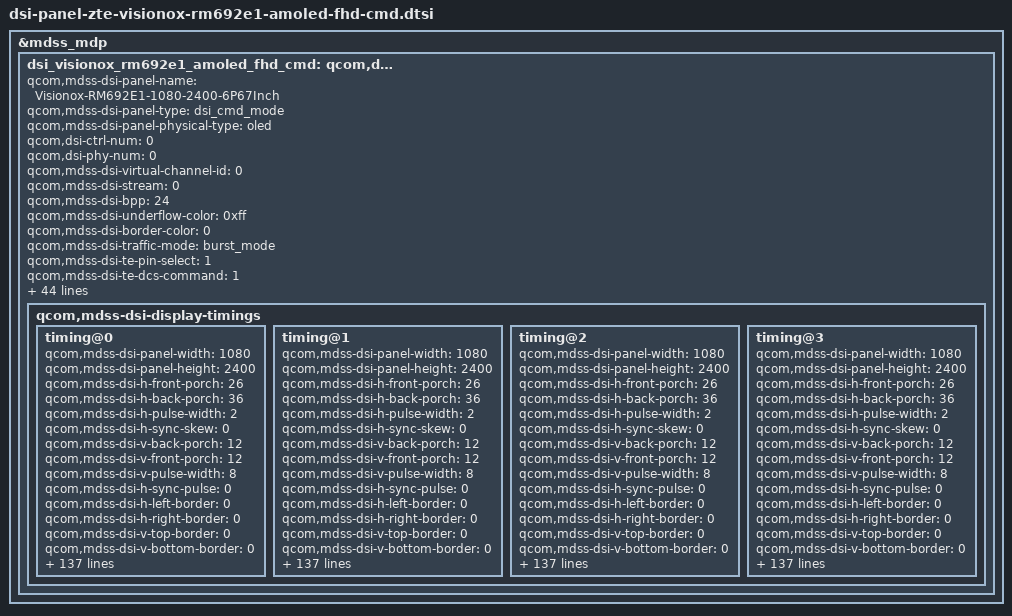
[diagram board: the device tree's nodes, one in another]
&mdss_mdp {
	dsi_visionox_rm692e1_amoled_fhd_cmd: qcom,dsi_visionox_rm692e1_cmd_display {
		qcom,mdss-dsi-panel-name = "Visionox-RM692E1-1080-2400-6P67Inch";
		qcom,mdss-dsi-panel-type = "dsi_cmd_mode";
		qcom,mdss-dsi-panel-physical-type = "oled";
		qcom,dsi-ctrl-num = <0>;
		qcom,dsi-phy-num = <0>;
		qcom,mdss-dsi-virtual-channel-id = <0>;
		qcom,mdss-dsi-stream = <0>;
		qcom,mdss-dsi-bpp = <24>;
		qcom,mdss-dsi-underflow-color = <0xff>;
		qcom,mdss-dsi-border-color = <0>;
		qcom,mdss-dsi-traffic-mode = "burst_mode";
		qcom,mdss-dsi-te-pin-select = <1>;
		qcom,mdss-dsi-te-dcs-command = <1>;
		qcom,mdss-dsi-te-check-enable;
		qcom,mdss-dsi-te-using-te-pin;
		qcom,mdss-dsi-bllp-eof-power-mode;
		qcom,mdss-dsi-bllp-power-mode;
		qcom,mdss-dsi-lane-0-state;
		qcom,mdss-dsi-lane-1-state;
		qcom,mdss-dsi-lane-2-state;
		qcom,mdss-dsi-lane-3-state;
		qcom,mdss-dsi-lp11-init;
		qcom,mdss-dsi-reset-sequence = <1 10 0 20 1 180>;
		qcom,mdss-dsi-tx-eot-append;
		qcom,mdss-dsi-post-init-delay = <1>;
		qcom,mdss-dsi-dma-trigger = "trigger_sw";
		qcom,mdss-dsi-mdp-trigger = "none";
		qcom,mdss-dsi-bl-min-level = <16>;
		qcom,mdss-dsi-bl-max-level = <2047>;
		qcom,bl-dsc-cmd-state = "dsi_lp_mode";
		qcom,mdss-dsi-bl-pmic-control-type = "bl_ctrl_dcs";
		qcom,mdss-dsi-panel-hdr-enabled;
		qcom,mdss-dsi-panel-hdr-color-primaries = <14500 15500 34015 15980 13030 34670 6950 2565>;
		qcom,mdss-dsi-panel-peak-brightness = <6680000>;
		qcom,mdss-dsi-panel-blackness-level = <20>;
		qcom,mdss-pan-physical-width-dimension = <69>;
		qcom,mdss-pan-physical-height-dimension = <155>;
		zte,lcd_dimreg_value = <40>;
		zte,lcd_close_dimreg_value = <32>;
		zte,lcd_aod_bl_reg51_control;
		zte,lcd_hbm_max_bl = <4095>;
		qcom,panel-supply-entries = <&dsi_panel_pwr_supply>;
		qcom,mdss-brightness-max-level = <255>;
		qcom,platform-reset-gpio = <&tlmm 24 0>;
		zte,disp_iovdd_en_gpio = <&pm8350_gpios 9 1>;
		qcom,mdss-dsi-bl-inverted-dbv;
		qcom,dsi-select-clocks = "mux_byte_clk0", "mux_pixel_clk0";
		qcom,dsi-panel-gpio-address = <0xf100000 0x1000>;
		qcom,dsi-panel-gpio-pins = <12 24 82>;
		qcom,dsi-panel-gpio-names = "reg-gpio", "reset-gpio", "platform-te-gpio";
		qcom,fod-dim-lut = <
			/* brightness alpha */
			0   244
			8   241
			16  239
			24  236
			32  235
			41  235
			49  235
			57  235
			65  235
			74  235
			82  226
			90  222
			98  218
			107 212
			115 206
			123 200
			131 190
			140 185
			148 181
			156 177
			164 173
			173 169
			181 165
			189 161
			197 157
			206 148
			214 140
			222 134
			230 130
			239 126
			247 112
			255 104
		>;

		qcom,mdss-dsi-display-timings {
			timing@0 {
				qcom,mdss-dsi-panel-width = <1080>;
				qcom,mdss-dsi-panel-height = <2400>;
				qcom,mdss-dsi-h-front-porch = <26>;
				qcom,mdss-dsi-h-back-porch = <36>;
				qcom,mdss-dsi-h-pulse-width = <2>;
				qcom,mdss-dsi-h-sync-skew = <0>;
				qcom,mdss-dsi-v-back-porch = <12>;
				qcom,mdss-dsi-v-front-porch = <12>;
				qcom,mdss-dsi-v-pulse-width = <8>;
				qcom,mdss-dsi-h-sync-pulse = <0>;
				qcom,mdss-dsi-h-left-border = <0>;
				qcom,mdss-dsi-h-right-border = <0>;
				qcom,mdss-dsi-v-top-border = <0>;
				qcom,mdss-dsi-v-bottom-border = <0>;
				qcom,mdss-dsi-panel-framerate = <60>;
				qcom,mdss-dsi-panel-clockrate = <925100000>;
				zte,mdss-dsi-60fps-to-90fps-commands = [15 01 00 00 00 00 02 fe 40
					15 01 00 00 00 00 02 bd 05
					15 01 00 00 00 00 02 fe 00
				];
				zte,mdss-dsi-60fps-to-90fps-commands-state = "dsi_lp_mode";
				zte,mdss-dsi-60fps-to-120fps-commands = [15 01 00 00 00 00 02 fe 00
					15 01 00 00 14 00 02 53 20
					15 01 00 00 32 00 02 03 06
					15 01 00 00 00 00 02 fe 00
					15 01 00 00 00 00 02 53 28
				];
				zte,mdss-dsi-60fps-to-120fps-commands-state = "dsi_lp_mode";
				zte,mdss-dsi-60fps-to-144fps-commands = [15 01 00 00 00 00 02 fe 00
					15 01 00 00 14 00 02 53 20
					15 01 00 00 32 00 02 03 06
					15 01 00 00 00 00 02 fe 40
					15 01 00 00 00 00 02 bd 07
					15 01 00 00 00 00 02 fe 00
					15 01 00 00 00 00 02 53 28
				];
				zte,mdss-dsi-60fps-to-144fps-commands-state = "dsi_lp_mode";
				zte,mdss-dsi-60fps-to-aod-commands = [15 01 00 00 00 00 02 fe 22
					15 01 00 00 00 00 02 5f 03
					15 01 00 00 00 00 02 fe 40
					15 01 00 00 00 00 02 15 13
					15 01 00 00 00 00 02 fe 00
					05 01 00 00 00 00 02 39 00
					15 01 00 00 00 00 02 fe 00
				];
				zte,mdss-dsi-60fps-to-aod-commands-state = "dsi_lp_mode";
				zte,mdss-dsi-90fps-to-60fps-commands = [15 01 00 00 00 00 02 fe 40
					15 01 00 00 00 00 02 bd 00
					15 01 00 00 00 00 02 fe 00
				];
				zte,mdss-dsi-90fps-to-60fps-commands-state = "dsi_lp_mode";
				zte,mdss-dsi-90fps-to-120fps-commands = [15 01 00 00 00 00 02 fe 00
					15 01 00 00 14 00 02 53 20
					15 01 00 00 00 00 02 fe 40
					15 01 00 00 00 00 02 bd 00
					15 01 00 00 00 00 02 fe 00
					15 01 00 00 32 00 02 03 06
					15 01 00 00 00 00 02 fe 00
					15 01 00 00 00 00 02 53 28
				];
				zte,mdss-dsi-90fps-to-120fps-commands-state = "dsi_lp_mode";
				zte,mdss-dsi-90fps-to-144fps-commands = [15 01 00 00 00 00 02 fe 00
					15 01 00 00 14 00 02 53 20
					15 01 00 00 00 00 02 fe 40
					15 01 00 00 00 00 02 bd 00
					15 01 00 00 00 00 02 fe 00
					15 01 00 00 32 00 02 03 06
					15 01 00 00 00 00 02 fe 40
					15 01 00 00 00 00 02 bd 07
					15 01 00 00 00 00 02 fe 00
					15 01 00 00 00 00 02 53 28
				];
				zte,mdss-dsi-90fps-to-144fps-commands-state = "dsi_lp_mode";
				zte,mdss-dsi-90fps-to-aod-commands = [15 01 00 00 00 00 02 fe 22
					15 01 00 00 00 00 02 5f 02
					15 01 00 00 00 00 02 fe 40
					15 01 00 00 00 00 02 bd 00
					15 01 00 00 00 00 02 fe 00
					05 01 00 00 00 00 02 39 00
					15 01 00 00 00 00 02 fe 00
				];
				zte,mdss-dsi-90fps-to-aod-commands-state = "dsi_lp_mode";
				zte,mdss-dsi-120fps-to-60fps-commands = [15 01 00 00 00 00 02 fe 00
					15 01 00 00 14 00 02 53 20
					15 01 00 00 32 00 02 03 00
					15 01 00 00 00 00 02 fe 00
					15 01 00 00 00 00 02 53 28
				];
				zte,mdss-dsi-120fps-to-60fps-commands-state = "dsi_lp_mode";
				zte,mdss-dsi-120fps-to-90fps-commands = [15 01 00 00 00 00 02 fe 00
					15 01 00 00 14 00 02 53 20
					15 01 00 00 32 00 02 03 00
					15 01 00 00 00 00 02 fe 40
					15 01 00 00 00 00 02 bd 05
					15 01 00 00 00 00 02 fe 00
					15 01 00 00 00 00 02 53 28
				];
				zte,mdss-dsi-120fps-to-90fps-commands-state = "dsi_lp_mode";
				zte,mdss-dsi-120fps-to-144fps-commands = [15 01 00 00 00 00 02 fe 40
					15 01 00 00 00 00 02 bd 07
					15 01 00 00 00 00 02 fe 00
				];
				zte,mdss-dsi-120fps-to-144fps-commands-state = "dsi_lp_mode";
				zte,mdss-dsi-120fps-to-aod-commands = [15 01 00 00 00 00 02 fe 22
					15 01 00 00 00 00 02 5f 02
					15 01 00 00 00 00 02 fe 00
					15 01 00 00 32 00 02 03 00
					15 01 00 00 00 00 02 fe 00
					05 01 00 00 00 00 02 39 00
				];
				zte,mdss-dsi-120fps-to-aod-commands-state = "dsi_lp_mode";
				zte,mdss-dsi-144fps-to-60fps-commands = [15 01 00 00 00 00 02 fe 00
					15 01 00 00 14 00 02 53 20
					15 01 00 00 00 00 02 fe 40
					15 01 00 00 00 00 02 bd 06
					15 01 00 00 00 00 02 fe 00
					15 01 00 00 32 00 02 03 00
					15 01 00 00 00 00 02 53 28
				];
				zte,mdss-dsi-144fps-to-60fps-commands-state = "dsi_lp_mode";
				zte,mdss-dsi-144fps-to-90fps-commands = [15 01 00 00 00 00 02 fe 00
					15 01 00 00 14 00 02 53 20
					15 01 00 00 00 00 02 fe 40
					15 01 00 00 00 00 02 bd 06
					15 01 00 00 00 00 02 fe 00
					15 01 00 00 32 00 02 03 00
					15 01 00 00 00 00 02 fe 40
					15 01 00 00 00 00 02 bd 05
					15 01 00 00 00 00 02 fe 00
					15 01 00 00 00 00 02 53 20
				];
				zte,mdss-dsi-144fps-to-90fps-commands-state = "dsi_lp_mode";
				zte,mdss-dsi-144fps-to-120fps-commands = [15 01 00 00 00 00 02 fe 40
					15 01 00 00 00 00 02 bd 06
					15 01 00 00 00 00 02 fe 00
				];
				zte,mdss-dsi-144fps-to-120fps-commands-state = "dsi_lp_mode";
				zte,mdss-dsi-144fps-to-aod-commands = [15 01 00 00 00 00 02 fe 22
					15 01 00 00 00 00 02 5f 02
					15 01 00 00 00 00 02 fe 40
					15 01 00 00 00 00 02 bd 06 
					15 01 00 00 00 00 02 fe 00
					15 01 00 00 32 00 02 03 00
					15 01 00 00 00 00 02 fe 00
					05 01 00 00 00 00 02 39 00
				];
				zte,mdss-dsi-144fps-to-aod-commands-state = "dsi_lp_mode";
				qcom,mdss-dsi-on-command = [15 01 00 00 00 00 02 fe 34
					15 01 00 00 00 00 02 47 03
					15 01 00 00 00 00 02 48 00
					15 01 00 00 00 00 02 00 00
					15 01 00 00 00 00 02 fe 34
					15 01 00 00 00 00 02 9f 38
					15 01 00 00 00 00 02 a0 04
					15 01 00 00 00 00 02 1e 33
					15 01 00 00 00 00 02 1f fc
					15 01 00 00 00 00 02 20 fc
					15 01 00 00 00 00 02 22 fc
					15 01 00 00 00 00 02 21 73
					15 01 00 00 00 00 02 23 f8
					15 01 00 00 00 00 02 24 77
					15 01 00 00 00 00 02 25 f8
					15 01 00 00 00 00 02 26 f8
					15 01 00 00 00 00 02 2f 00
					15 01 00 00 00 00 02 30 00
					15 01 00 00 00 00 02 31 00
					15 01 00 00 00 00 02 32 00
					15 01 00 00 00 00 02 33 00
					15 01 00 00 00 00 02 34 00
					15 01 00 00 00 00 02 35 01
					15 01 00 00 00 00 02 36 47
					15 01 00 00 00 00 02 37 02
					15 01 00 00 00 00 02 38 3e
					15 01 00 00 00 00 02 39 03
					15 01 00 00 00 00 02 3a 33
					15 01 00 00 00 00 02 3b 00
					15 01 00 00 00 00 02 3d 00
					15 01 00 00 00 00 02 3f 00
					15 01 00 00 00 00 02 40 00
					15 01 00 00 00 00 02 41 00
					15 01 00 00 00 00 02 42 00
					15 01 00 00 00 00 02 fe 34
					15 01 00 00 00 00 02 49 75
					15 01 00 00 00 00 02 fe 76
					15 01 00 00 00 00 02 00 3c
					15 01 00 00 00 00 02 09 03
					15 01 00 00 00 00 02 0a 00
					15 01 00 00 00 00 02 0b 06
					15 01 00 00 00 00 02 0c 70
					15 01 00 00 00 00 02 0d 76
					15 01 00 00 00 00 02 0e 0d
					15 01 00 00 00 00 02 0f 03
					15 01 00 00 00 00 02 10 00
					15 01 00 00 00 00 02 11 00
					15 01 00 00 00 00 02 12 80
					15 01 00 00 00 00 02 13 76
					15 01 00 00 00 00 02 14 0d
					15 01 00 00 00 00 02 fe 76
					15 01 00 00 00 00 02 70 fe
					15 01 00 00 00 00 02 71 40
					15 01 00 00 00 00 02 72 bd
					15 01 00 00 00 00 02 73 06
					15 01 00 00 00 00 02 74 ff
					15 01 00 00 00 00 02 75 01
					15 01 00 00 00 00 02 76 02
					15 01 00 00 00 00 02 77 fe
					15 01 00 00 00 00 02 78 62
					15 01 00 00 00 00 02 79 ee
					15 01 00 00 00 00 02 7a 20
					15 01 00 00 00 00 02 7b fe
					15 01 00 00 00 00 02 7c 00
					15 01 00 00 00 00 02 80 fe
					15 01 00 00 00 00 02 81 40
					15 01 00 00 00 00 02 82 bd
					15 01 00 00 00 00 02 83 00
					15 01 00 00 00 00 02 84 ff
					15 01 00 00 00 00 02 85 01
					15 01 00 00 00 00 02 86 02
					15 01 00 00 00 00 02 87 fe
					15 01 00 00 00 00 02 88 62
					15 01 00 00 00 00 02 89 ee
					15 01 00 00 00 00 02 8a 10
					15 01 00 00 00 00 02 8b fe
					15 01 00 00 00 00 02 8c 00
					15 01 00 00 00 00 02 fe d0
					15 01 00 00 00 00 02 14 c0
					15 01 00 00 00 00 02 15 c0
					15 01 00 00 00 00 02 fe 12
					15 01 00 00 00 00 02 83 20
					15 01 00 00 00 00 02 fe 00
					15 01 00 00 00 00 02 fa 01
					15 01 00 00 00 00 02 c2 08
					15 01 00 00 00 00 02 35 00
					39 01 00 00 00 00 03 51 00 00
					15 01 00 00 00 00 02 fe b0
					15 01 00 00 00 00 02 27 7f
					15 01 00 00 00 00 02 fe 62
					15 01 00 00 00 00 02 0f f0
					15 01 00 00 00 00 02 10 00
					15 01 00 00 00 00 02 fe 60
					15 01 00 00 00 00 02 7e 50
					15 01 00 00 00 00 02 80 98
					15 01 00 00 00 00 02 81 20
					15 01 00 00 00 00 02 0d 50
					15 01 00 00 00 00 02 0f 98
					15 01 00 00 00 00 02 10 20
					15 01 00 00 00 00 02 28 50
					15 01 00 00 00 00 02 2a 90
					15 01 00 00 00 00 02 2b 05
					15 01 00 00 00 00 02 47 50
					15 01 00 00 00 00 02 49 90
					15 01 00 00 00 00 02 4a 05
					15 01 00 00 00 00 02 fe 60
					15 01 00 00 00 00 02 92 e5
					15 01 00 00 00 00 02 94 00
					15 01 00 00 00 00 02 fe d4
					15 01 00 00 00 00 02 14 83
					15 01 00 00 00 00 02 1e 00
					15 01 00 00 00 00 02 1f 08
					15 01 00 00 00 00 02 20 0c
					15 01 00 00 00 00 02 21 03
					15 01 00 00 00 00 02 22 8e
					15 01 00 00 00 00 02 23 03
					15 01 00 00 00 00 02 24 e8
					15 01 00 00 00 00 02 25 00
					15 01 00 00 00 00 02 26 08
					15 01 00 00 00 00 02 27 0c
					15 01 00 00 00 00 02 28 03
					15 01 00 00 00 00 02 29 8e
					15 01 00 00 00 00 02 2a 03
					15 01 00 00 00 00 02 2b e8
					15 01 00 00 00 00 02 2d 00
					15 01 00 00 00 00 02 2f 08
					15 01 00 00 00 00 02 30 0c
					15 01 00 00 00 00 02 31 03
					15 01 00 00 00 00 02 32 8e
					15 01 00 00 00 00 02 33 03
					15 01 00 00 00 00 02 34 e8
					15 01 00 00 00 00 02 35 00
					15 01 00 00 00 00 02 36 08
					15 01 00 00 00 00 02 37 0c
					15 01 00 00 00 00 02 38 03
					15 01 00 00 00 00 02 39 8e
					15 01 00 00 00 00 02 3a 03
					15 01 00 00 00 00 02 3b e8
					15 01 00 00 00 00 02 fe 14
					15 01 00 00 00 00 02 a2 01
					15 01 00 00 00 00 02 51 80
					15 01 00 00 00 00 02 7b 00
					15 01 00 00 00 00 02 fe 40
					15 01 00 00 00 00 02 25 1a
					15 01 00 00 00 00 02 26 1d
					15 01 00 00 00 00 02 ac 84
					15 01 00 00 00 00 02 31 00
					15 01 00 00 00 00 02 35 00
					15 01 00 00 00 00 02 fe 00
					05 01 00 00 50 00 02 11 00
					05 01 00 00 0a 00 02 29 00
				];
				qcom,mdss-dsi-off-command = [39 01 00 00 14 00 03 51 00 00
					05 01 00 00 32 00 02 28 00
					05 01 00 00 50 00 02 10 00
				];
				qcom,mdss-dsi-on-command-state = "dsi_lp_mode";
				qcom,mdss-dsi-off-command-state = "dsi_lp_mode";
				qcom,mdss-dsi-lp1-command = [15 01 00 00 00 00 02 fe 22
					15 01 00 00 00 00 02 5f 03
					15 01 00 00 00 00 02 fe 40
					15 01 00 00 00 00 02 15 13
					15 01 00 00 00 00 02 fe 00
					05 01 00 00 00 00 02 39 00
					15 01 00 00 00 00 02 fe 00
				];
				qcom,mdss-dsi-lp1-command-state = "dsi_lp_mode";
				qcom,mdss-dsi-nolp-command = [15 01 00 00 00 00 02 fe 22
					15 01 00 00 00 00 02 5f 01
					15 01 00 00 00 00 02 fe 40
					15 01 00 00 00 00 02 15 4f
					15 01 00 00 00 00 02 fe 00
					05 01 00 00 00 00 02 38 00
					15 01 00 00 00 00 02 fe 00
				];
				qcom,mdss-dsi-nolp-command-state = "dsi_lp_mode";
				zte,mdss-dsi-aod-low-commands = [15 01 00 00 00 00 02 fe 00
					39 01 00 00 00 00 03 51 01 20
				];
				zte,mdss-dsi-aod-mid-commands = [15 01 00 00 00 00 02 fe 00
					39 01 00 00 00 00 03 51 07 ff
				];
				zte,mdss-dsi-aod-high-commands = [15 01 00 00 00 00 02 fe 00
					39 01 00 00 00 00 03 51 0f ff
				];
				zte,mdss-dsi-color-original-commands = [15 01 00 00 00 00 02 fe 12
					15 01 00 00 00 00 02 83 00
					15 01 00 00 05 00 02 fe 00
				];
				zte,mdss-dsi-color-srgb-commands = [15 01 00 00 00 00 02 fe 12
					15 01 00 00 00 00 02 83 10
					15 01 00 00 05 00 02 fe 00
				];
				zte,mdss-dsi-color-p3-commands = [15 01 00 00 00 00 02 fe 12
					15 01 00 00 00 00 02 83 20
					15 01 00 00 05 00 02 fe 00
				];
				zte,mdss-dsi-hbm-on-commands = [15 01 00 00 00 00 02 fe 00
					15 01 00 00 00 00 02 53 20
					39 01 00 00 00 00 03 51 0f ff
				];
				zte,mdss-dsi-hbm-off-commands = [15 01 00 00 00 00 02 53 20];
				zte,mdss-dsi-acl-off-commands = [15 01 00 00 00 00 02 fe 00
					15 01 00 00 00 00 02 55 00
				];
				zte,mdss-dsi-acl-low-commands = [15 01 00 00 00 00 02 fe 00
					15 01 00 00 00 00 02 55 11
				];
				zte,mdss-dsi-acl-mid-commands = [15 01 00 00 00 00 02 fe 00
					15 01 00 00 00 00 02 55 12
				];
				zte,mdss-dsi-acl-high-commands = [15 01 00 00 00 00 02 fe 00
					15 01 00 00 00 00 02 55 13
				];
				zte,mdss-dsi-acl-off-commands-state = "dsi_lp_mode";
				zte,mdss-dsi-acl-low-commands-state = "dsi_lp_mode";
				zte,mdss-dsi-acl-mid-commands-state = "dsi_lp_mode";
				zte,mdss-dsi-acl-high-commands-state = "dsi_lp_mode";
				zte,mdss-dsi-hbm-on-commands-state = "dsi_lp_mode";
				zte,mdss-dsi-hbm-off-commands-state = "dsi_lp_mode";
				zte,mdss-dsi-color-original-commands-state = "dsi_hs_mode";
				zte,mdss-dsi-color-srgb-commands-state = "dsi_hs_mode";
				zte,mdss-dsi-color-p3-commands-state = "dsi_hs_mode";
				zte,mdss-dsi-aod-low-commands-state = "dsi_lp_mode";
				zte,mdss-dsi-aod-mid-commands-state = "dsi_lp_mode";
				zte,mdss-dsi-aod-high-commands-state = "dsi_lp_mode";
				qcom,compression-mode = "dsc";
				qcom,mdss-dsc-slice-height = <12>;
				qcom,mdss-dsc-slice-width = <540>;
				qcom,mdss-dsc-slice-per-pkt = <2>;
				qcom,mdss-dsc-bit-per-component = <10>;
				qcom,mdss-dsc-bit-per-pixel = <8>;
				qcom,mdss-dsc-block-prediction-enable;
				qcom,mdss-dsi-panel-phy-timings = [00 10 03 03 11 1e 04 04 03 02 04 00 0e 08];
				qcom,display-topology = <2 2 1>;
				qcom,default-topology-index = <0>;
			};

			timing@1 {
				qcom,mdss-dsi-panel-width = <1080>;
				qcom,mdss-dsi-panel-height = <2400>;
				qcom,mdss-dsi-h-front-porch = <26>;
				qcom,mdss-dsi-h-back-porch = <36>;
				qcom,mdss-dsi-h-pulse-width = <2>;
				qcom,mdss-dsi-h-sync-skew = <0>;
				qcom,mdss-dsi-v-back-porch = <12>;
				qcom,mdss-dsi-v-front-porch = <12>;
				qcom,mdss-dsi-v-pulse-width = <8>;
				qcom,mdss-dsi-h-sync-pulse = <0>;
				qcom,mdss-dsi-h-left-border = <0>;
				qcom,mdss-dsi-h-right-border = <0>;
				qcom,mdss-dsi-v-top-border = <0>;
				qcom,mdss-dsi-v-bottom-border = <0>;
				qcom,mdss-dsi-panel-framerate = <90>;
				qcom,mdss-dsi-panel-clockrate = <925200000>;
				zte,mdss-dsi-60fps-to-90fps-commands = [15 01 00 00 00 00 02 fe 40
					15 01 00 00 00 00 02 bd 05
					15 01 00 00 00 00 02 fe 00
				];
				zte,mdss-dsi-60fps-to-90fps-commands-state = "dsi_lp_mode";
				zte,mdss-dsi-60fps-to-120fps-commands = [15 01 00 00 00 00 02 fe 00
					15 01 00 00 14 00 02 53 20
					15 01 00 00 32 00 02 03 06
					15 01 00 00 00 00 02 fe 00
					15 01 00 00 00 00 02 53 28
				];
				zte,mdss-dsi-60fps-to-120fps-commands-state = "dsi_lp_mode";
				zte,mdss-dsi-60fps-to-144fps-commands = [15 01 00 00 00 00 02 fe 00
					15 01 00 00 14 00 02 53 20
					15 01 00 00 32 00 02 03 06
					15 01 00 00 00 00 02 fe 40
					15 01 00 00 00 00 02 bd 07
					15 01 00 00 00 00 02 fe 00
					15 01 00 00 00 00 02 53 28
				];
				zte,mdss-dsi-60fps-to-144fps-commands-state = "dsi_lp_mode";
				zte,mdss-dsi-60fps-to-aod-commands = [15 01 00 00 00 00 02 fe 22
					15 01 00 00 00 00 02 5f 03
					15 01 00 00 00 00 02 fe 40
					15 01 00 00 00 00 02 15 13
					15 01 00 00 00 00 02 fe 00
					05 01 00 00 00 00 02 39 00
					15 01 00 00 00 00 02 fe 00
				];
				zte,mdss-dsi-60fps-to-aod-commands-state = "dsi_lp_mode";
				zte,mdss-dsi-90fps-to-60fps-commands = [15 01 00 00 00 00 02 fe 40
					15 01 00 00 00 00 02 bd 00
					15 01 00 00 00 00 02 fe 00
				];
				zte,mdss-dsi-90fps-to-60fps-commands-state = "dsi_lp_mode";
				zte,mdss-dsi-90fps-to-120fps-commands = [15 01 00 00 00 00 02 fe 00
					15 01 00 00 14 00 02 53 20
					15 01 00 00 00 00 02 fe 40
					15 01 00 00 00 00 02 bd 00
					15 01 00 00 00 00 02 fe 00
					15 01 00 00 32 00 02 03 06
					15 01 00 00 00 00 02 fe 00
					15 01 00 00 00 00 02 53 28
				];
				zte,mdss-dsi-90fps-to-120fps-commands-state = "dsi_lp_mode";
				zte,mdss-dsi-90fps-to-144fps-commands = [15 01 00 00 00 00 02 fe 00
					15 01 00 00 14 00 02 53 20
					15 01 00 00 00 00 02 fe 40
					15 01 00 00 00 00 02 bd 00
					15 01 00 00 00 00 02 fe 00
					15 01 00 00 32 00 02 03 06
					15 01 00 00 00 00 02 fe 40
					15 01 00 00 00 00 02 bd 07
					15 01 00 00 00 00 02 fe 00
					15 01 00 00 00 00 02 53 28
				];
				zte,mdss-dsi-90fps-to-144fps-commands-state = "dsi_lp_mode";
				zte,mdss-dsi-90fps-to-aod-commands = [15 01 00 00 00 00 02 fe 22
					15 01 00 00 00 00 02 5f 02
					15 01 00 00 00 00 02 fe 40
					15 01 00 00 00 00 02 bd 00
					15 01 00 00 00 00 02 fe 00
					05 01 00 00 00 00 02 39 00
					15 01 00 00 00 00 02 fe 00
				];
				zte,mdss-dsi-90fps-to-aod-commands-state = "dsi_lp_mode";
				zte,mdss-dsi-120fps-to-60fps-commands = [15 01 00 00 00 00 02 fe 00
					15 01 00 00 14 00 02 53 20
					15 01 00 00 32 00 02 03 00
					15 01 00 00 00 00 02 fe 00
					15 01 00 00 00 00 02 53 28
				];
				zte,mdss-dsi-120fps-to-60fps-commands-state = "dsi_lp_mode";
				zte,mdss-dsi-120fps-to-90fps-commands = [15 01 00 00 00 00 02 fe 00
					15 01 00 00 14 00 02 53 20
					15 01 00 00 32 00 02 03 00
					15 01 00 00 00 00 02 fe 40
					15 01 00 00 00 00 02 bd 05
					15 01 00 00 00 00 02 fe 00
					15 01 00 00 00 00 02 53 28
				];
				zte,mdss-dsi-120fps-to-90fps-commands-state = "dsi_lp_mode";
				zte,mdss-dsi-120fps-to-144fps-commands = [15 01 00 00 00 00 02 fe 40
					15 01 00 00 00 00 02 bd 07
					15 01 00 00 00 00 02 fe 00
				];
				zte,mdss-dsi-120fps-to-144fps-commands-state = "dsi_lp_mode";
				zte,mdss-dsi-120fps-to-aod-commands = [15 01 00 00 00 00 02 fe 22
					15 01 00 00 00 00 02 5f 02
					15 01 00 00 00 00 02 fe 00
					15 01 00 00 32 00 02 03 00
					15 01 00 00 00 00 02 fe 00
					05 01 00 00 00 00 02 39 00
				];
				zte,mdss-dsi-120fps-to-aod-commands-state = "dsi_lp_mode";
				zte,mdss-dsi-144fps-to-60fps-commands = [15 01 00 00 00 00 02 fe 00
					15 01 00 00 14 00 02 53 20
					15 01 00 00 00 00 02 fe 40
					15 01 00 00 00 00 02 bd 06
					15 01 00 00 00 00 02 fe 00
					15 01 00 00 32 00 02 03 00
					15 01 00 00 00 00 02 53 28
				];
				zte,mdss-dsi-144fps-to-60fps-commands-state = "dsi_lp_mode";
				zte,mdss-dsi-144fps-to-90fps-commands = [15 01 00 00 00 00 02 fe 00
					15 01 00 00 14 00 02 53 20
					15 01 00 00 00 00 02 fe 40
					15 01 00 00 00 00 02 bd 06
					15 01 00 00 00 00 02 fe 00
					15 01 00 00 32 00 02 03 00
					15 01 00 00 00 00 02 fe 40
					15 01 00 00 00 00 02 bd 05
					15 01 00 00 00 00 02 fe 00
					15 01 00 00 00 00 02 53 28
				];
				zte,mdss-dsi-144fps-to-90fps-commands-state = "dsi_lp_mode";
				zte,mdss-dsi-144fps-to-120fps-commands = [15 01 00 00 00 00 02 fe 40
					15 01 00 00 00 00 02 bd 06
					15 01 00 00 00 00 02 fe 00
				];
				zte,mdss-dsi-144fps-to-120fps-commands-state = "dsi_lp_mode";
				zte,mdss-dsi-144fps-to-aod-commands = [15 01 00 00 00 00 02 fe 22
					15 01 00 00 00 00 02 5f 02
					15 01 00 00 00 00 02 fe 40
					15 01 00 00 00 00 02 bd 06 
					15 01 00 00 00 00 02 fe 00
					15 01 00 00 32 00 02 03 00
					15 01 00 00 00 00 02 fe 00
					05 01 00 00 00 00 02 39 00
				];
				zte,mdss-dsi-144fps-to-aod-commands-state = "dsi_lp_mode";
				qcom,mdss-dsi-on-command = [15 01 00 00 00 00 02 fe 34
					15 01 00 00 00 00 02 47 03
					15 01 00 00 00 00 02 48 00
					15 01 00 00 00 00 02 00 00
					15 01 00 00 00 00 02 fe 34
					15 01 00 00 00 00 02 9f 38
					15 01 00 00 00 00 02 a0 04
					15 01 00 00 00 00 02 1e 33
					15 01 00 00 00 00 02 1f fc
					15 01 00 00 00 00 02 20 fc
					15 01 00 00 00 00 02 22 fc
					15 01 00 00 00 00 02 21 73
					15 01 00 00 00 00 02 23 f8
					15 01 00 00 00 00 02 24 77
					15 01 00 00 00 00 02 25 f8
					15 01 00 00 00 00 02 26 f8
					15 01 00 00 00 00 02 2f 00
					15 01 00 00 00 00 02 30 00
					15 01 00 00 00 00 02 31 00
					15 01 00 00 00 00 02 32 00
					15 01 00 00 00 00 02 33 00
					15 01 00 00 00 00 02 34 00
					15 01 00 00 00 00 02 35 01
					15 01 00 00 00 00 02 36 47
					15 01 00 00 00 00 02 37 02
					15 01 00 00 00 00 02 38 3e
					15 01 00 00 00 00 02 39 03
					15 01 00 00 00 00 02 3a 33
					15 01 00 00 00 00 02 3b 00
					15 01 00 00 00 00 02 3d 00
					15 01 00 00 00 00 02 3f 00
					15 01 00 00 00 00 02 40 00
					15 01 00 00 00 00 02 41 00
					15 01 00 00 00 00 02 42 00
					15 01 00 00 00 00 02 fe 34
					15 01 00 00 00 00 02 49 75
					15 01 00 00 00 00 02 fe 76
					15 01 00 00 00 00 02 00 3c
					15 01 00 00 00 00 02 09 03
					15 01 00 00 00 00 02 0a 00
					15 01 00 00 00 00 02 0b 06
					15 01 00 00 00 00 02 0c 70
					15 01 00 00 00 00 02 0d 76
					15 01 00 00 00 00 02 0e 0d
					15 01 00 00 00 00 02 0f 03
					15 01 00 00 00 00 02 10 00
					15 01 00 00 00 00 02 11 00
					15 01 00 00 00 00 02 12 80
					15 01 00 00 00 00 02 13 76
					15 01 00 00 00 00 02 14 0d
					15 01 00 00 00 00 02 fe 76
					15 01 00 00 00 00 02 70 fe
					15 01 00 00 00 00 02 71 40
					15 01 00 00 00 00 02 72 bd
					15 01 00 00 00 00 02 73 06
					15 01 00 00 00 00 02 74 ff
					15 01 00 00 00 00 02 75 01
					15 01 00 00 00 00 02 76 02
					15 01 00 00 00 00 02 77 fe
					15 01 00 00 00 00 02 78 62
					15 01 00 00 00 00 02 79 ee
					15 01 00 00 00 00 02 7a 20
					15 01 00 00 00 00 02 7b fe
					15 01 00 00 00 00 02 7c 00
					15 01 00 00 00 00 02 80 fe
					15 01 00 00 00 00 02 81 40
					15 01 00 00 00 00 02 82 bd
					15 01 00 00 00 00 02 83 00
					15 01 00 00 00 00 02 84 ff
					15 01 00 00 00 00 02 85 01
					15 01 00 00 00 00 02 86 02
					15 01 00 00 00 00 02 87 fe
					15 01 00 00 00 00 02 88 62
					15 01 00 00 00 00 02 89 ee
					15 01 00 00 00 00 02 8a 10
					15 01 00 00 00 00 02 8b fe
					15 01 00 00 00 00 02 8c 00
					15 01 00 00 00 00 02 fe d0
					15 01 00 00 00 00 02 14 c0
					15 01 00 00 00 00 02 15 c0
					15 01 00 00 00 00 02 fe 12
					15 01 00 00 00 00 02 83 20
					15 01 00 00 00 00 02 fe 00
					15 01 00 00 00 00 02 fa 01
					15 01 00 00 00 00 02 c2 08
					15 01 00 00 00 00 02 35 00
					39 01 00 00 00 00 03 51 00 00
					15 01 00 00 00 00 02 fe b0
					15 01 00 00 00 00 02 27 7f
					15 01 00 00 00 00 02 fe 62
					15 01 00 00 00 00 02 0f f0
					15 01 00 00 00 00 02 10 00
					15 01 00 00 00 00 02 fe 60
					15 01 00 00 00 00 02 7e 50
					15 01 00 00 00 00 02 80 98
					15 01 00 00 00 00 02 81 20
					15 01 00 00 00 00 02 0d 50
					15 01 00 00 00 00 02 0f 98
					15 01 00 00 00 00 02 10 20
					15 01 00 00 00 00 02 28 50
					15 01 00 00 00 00 02 2a 90
					15 01 00 00 00 00 02 2b 05
					15 01 00 00 00 00 02 47 50
					15 01 00 00 00 00 02 49 90
					15 01 00 00 00 00 02 4a 05
					15 01 00 00 00 00 02 fe 60
					15 01 00 00 00 00 02 92 e5
					15 01 00 00 00 00 02 94 00
					15 01 00 00 00 00 02 fe d4
					15 01 00 00 00 00 02 14 83
					15 01 00 00 00 00 02 1e 00
					15 01 00 00 00 00 02 1f 08
					15 01 00 00 00 00 02 20 0c
					15 01 00 00 00 00 02 21 03
					15 01 00 00 00 00 02 22 8e
					15 01 00 00 00 00 02 23 03
					15 01 00 00 00 00 02 24 e8
					15 01 00 00 00 00 02 25 00
					15 01 00 00 00 00 02 26 08
					15 01 00 00 00 00 02 27 0c
					15 01 00 00 00 00 02 28 03
					15 01 00 00 00 00 02 29 8e
					15 01 00 00 00 00 02 2a 03
					15 01 00 00 00 00 02 2b e8
					15 01 00 00 00 00 02 2d 00
					15 01 00 00 00 00 02 2f 08
					15 01 00 00 00 00 02 30 0c
					15 01 00 00 00 00 02 31 03
					15 01 00 00 00 00 02 32 8e
					15 01 00 00 00 00 02 33 03
					15 01 00 00 00 00 02 34 e8
					15 01 00 00 00 00 02 35 00
					15 01 00 00 00 00 02 36 08
					15 01 00 00 00 00 02 37 0c
					15 01 00 00 00 00 02 38 03
					15 01 00 00 00 00 02 39 8e
					15 01 00 00 00 00 02 3a 03
					15 01 00 00 00 00 02 3b e8
					15 01 00 00 00 00 02 fe 14
					15 01 00 00 00 00 02 a2 01
					15 01 00 00 00 00 02 51 80
					15 01 00 00 00 00 02 7b 00
					15 01 00 00 00 00 02 fe 40
					15 01 00 00 00 00 02 25 1a
					15 01 00 00 00 00 02 26 1d
					15 01 00 00 00 00 02 ac 84
					15 01 00 00 00 00 02 31 00
					15 01 00 00 00 00 02 35 00
					15 01 00 00 00 00 02 fe 00
					05 01 00 00 50 00 02 11 00
					05 01 00 00 0a 00 02 29 00
					15 01 00 00 00 00 02 fe 40
					15 01 00 00 00 00 02 bd 05
					15 01 00 00 00 00 02 fe 00
				];
				qcom,mdss-dsi-off-command = [39 01 00 00 50 00 03 51 00 00
					05 01 00 00 32 00 02 28 00
					05 01 00 00 50 00 02 10 00
				];
				qcom,mdss-dsi-on-command-state = "dsi_lp_mode";
				qcom,mdss-dsi-off-command-state = "dsi_lp_mode";
				qcom,mdss-dsi-lp1-command = [15 01 00 00 00 00 02 fe 22
					15 01 00 00 00 00 02 5f 02
					15 01 00 00 00 00 02 fe 40
					15 01 00 00 00 00 02 bd 00
					15 01 00 00 00 00 02 fe 00
					05 01 00 00 00 00 02 39 00
					15 01 00 00 00 00 02 fe 00
				];
				qcom,mdss-dsi-lp1-command-state = "dsi_lp_mode";
				qcom,mdss-dsi-nolp-command = [15 01 00 00 00 00 02 fe 22
					15 01 00 00 00 00 02 5f 01
					15 01 00 00 00 00 02 fe 40
					15 01 00 00 00 00 02 15 4f
					15 01 00 00 00 00 02 fe 00
					05 01 00 00 00 00 02 38 00
					15 01 00 00 00 00 02 fe 40
					15 01 00 00 00 00 02 bd 05
					15 01 00 00 00 00 02 fe 00
				];
				qcom,mdss-dsi-nolp-command-state = "dsi_lp_mode";
				zte,mdss-dsi-aod-low-commands = [15 01 00 00 00 00 02 fe 00
					39 01 00 00 00 00 03 51 01 20
				];
				zte,mdss-dsi-aod-mid-commands = [15 01 00 00 00 00 02 fe 00
					39 01 00 00 00 00 03 51 07 ff
				];
				zte,mdss-dsi-aod-high-commands = [15 01 00 00 00 00 02 fe 00
					39 01 00 00 00 00 03 51 0f ff
				];
				zte,mdss-dsi-color-original-commands = [15 01 00 00 00 00 02 fe 12
					15 01 00 00 00 00 02 83 00
					15 01 00 00 05 00 02 fe 00
				];
				zte,mdss-dsi-color-srgb-commands = [15 01 00 00 00 00 02 fe 12
					15 01 00 00 00 00 02 83 10
					15 01 00 00 05 00 02 fe 00
				];
				zte,mdss-dsi-color-p3-commands = [15 01 00 00 00 00 02 fe 12
					15 01 00 00 00 00 02 83 20
					15 01 00 00 05 00 02 fe 00
				];
				zte,mdss-dsi-hbm-on-commands = [15 01 00 00 00 00 02 fe 00
					15 01 00 00 00 00 02 53 20
					39 01 00 00 00 00 03 51 0f ff
				];
				zte,mdss-dsi-hbm-off-commands = [15 01 00 00 00 00 02 53 20];
				zte,mdss-dsi-acl-off-commands = [15 01 00 00 00 00 02 fe 00
					15 01 00 00 00 00 02 55 00
				];
				zte,mdss-dsi-acl-low-commands = [15 01 00 00 00 00 02 fe 00
					15 01 00 00 00 00 02 55 11
				];
				zte,mdss-dsi-acl-mid-commands = [15 01 00 00 00 00 02 fe 00
					15 01 00 00 00 00 02 55 12
				];
				zte,mdss-dsi-acl-high-commands = [15 01 00 00 00 00 02 fe 00
					15 01 00 00 00 00 02 55 13
				];
				zte,mdss-dsi-acl-off-commands-state = "dsi_lp_mode";
				zte,mdss-dsi-acl-low-commands-state = "dsi_lp_mode";
				zte,mdss-dsi-acl-mid-commands-state = "dsi_lp_mode";
				zte,mdss-dsi-acl-high-commands-state = "dsi_lp_mode";
				zte,mdss-dsi-hbm-on-commands-state = "dsi_lp_mode";
				zte,mdss-dsi-hbm-off-commands-state = "dsi_lp_mode";
				zte,mdss-dsi-color-original-commands-state = "dsi_hs_mode";
				zte,mdss-dsi-color-srgb-commands-state = "dsi_hs_mode";
				zte,mdss-dsi-color-p3-commands-state = "dsi_hs_mode";
				zte,mdss-dsi-aod-low-commands-state = "dsi_lp_mode";
				zte,mdss-dsi-aod-mid-commands-state = "dsi_lp_mode";
				zte,mdss-dsi-aod-high-commands-state = "dsi_lp_mode";
				qcom,compression-mode = "dsc";
				qcom,mdss-dsc-slice-height = <12>;
				qcom,mdss-dsc-slice-width = <540>;
				qcom,mdss-dsc-slice-per-pkt = <2>;
				qcom,mdss-dsc-bit-per-component = <10>;
				qcom,mdss-dsc-bit-per-pixel = <8>;
				qcom,mdss-dsc-block-prediction-enable;
				qcom,mdss-dsi-panel-phy-timings = [00 15 05 05 14 1f 05 05 06 02 04 00 13 0a];
				qcom,display-topology = <2 2 1>;
				qcom,default-topology-index = <0>;
			};

			timing@2 {
				qcom,mdss-dsi-panel-width = <1080>;
				qcom,mdss-dsi-panel-height = <2400>;
				qcom,mdss-dsi-h-front-porch = <26>;
				qcom,mdss-dsi-h-back-porch = <36>;
				qcom,mdss-dsi-h-pulse-width = <2>;
				qcom,mdss-dsi-h-sync-skew = <0>;
				qcom,mdss-dsi-v-back-porch = <12>;
				qcom,mdss-dsi-v-front-porch = <12>;
				qcom,mdss-dsi-v-pulse-width = <8>;
				qcom,mdss-dsi-h-sync-pulse = <0>;
				qcom,mdss-dsi-h-left-border = <0>;
				qcom,mdss-dsi-h-right-border = <0>;
				qcom,mdss-dsi-v-top-border = <0>;
				qcom,mdss-dsi-v-bottom-border = <0>;
				qcom,mdss-dsi-panel-framerate = <120>;
				qcom,mdss-dsi-panel-clockrate = <925300000>;
				zte,mdss-dsi-60fps-to-90fps-commands = [15 01 00 00 00 00 02 fe 40
					15 01 00 00 00 00 02 bd 05
					15 01 00 00 00 00 02 fe 00
				];
				zte,mdss-dsi-60fps-to-90fps-commands-state = "dsi_lp_mode";
				zte,mdss-dsi-60fps-to-120fps-commands = [15 01 00 00 00 00 02 fe 00
					15 01 00 00 14 00 02 53 20
					15 01 00 00 32 00 02 03 06
					15 01 00 00 00 00 02 fe 00
					15 01 00 00 00 00 02 53 28
				];
				zte,mdss-dsi-60fps-to-120fps-commands-state = "dsi_lp_mode";
				zte,mdss-dsi-60fps-to-144fps-commands = [15 01 00 00 00 00 02 fe 00
					15 01 00 00 14 00 02 53 20
					15 01 00 00 32 00 02 03 06
					15 01 00 00 00 00 02 fe 40
					15 01 00 00 00 00 02 bd 07
					15 01 00 00 00 00 02 fe 00
					15 01 00 00 00 00 02 53 28
				];
				zte,mdss-dsi-60fps-to-144fps-commands-state = "dsi_lp_mode";
				zte,mdss-dsi-60fps-to-aod-commands = [15 01 00 00 00 00 02 fe 22
					15 01 00 00 00 00 02 5f 03
					15 01 00 00 00 00 02 fe 40
					15 01 00 00 00 00 02 15 13
					15 01 00 00 00 00 02 fe 00
					05 01 00 00 00 00 02 39 00
					15 01 00 00 00 00 02 fe 00
				];
				zte,mdss-dsi-60fps-to-aod-commands-state = "dsi_lp_mode";
				zte,mdss-dsi-90fps-to-60fps-commands = [15 01 00 00 00 00 02 fe 40
					15 01 00 00 00 00 02 bd 00
					15 01 00 00 00 00 02 fe 00
				];
				zte,mdss-dsi-90fps-to-60fps-commands-state = "dsi_lp_mode";
				zte,mdss-dsi-90fps-to-120fps-commands = [15 01 00 00 00 00 02 fe 00
					15 01 00 00 14 00 02 53 20
					15 01 00 00 00 00 02 fe 40
					15 01 00 00 00 00 02 bd 00
					15 01 00 00 00 00 02 fe 00
					15 01 00 00 32 00 02 03 06
					15 01 00 00 00 00 02 fe 00
					15 01 00 00 00 00 02 53 28
				];
				zte,mdss-dsi-90fps-to-120fps-commands-state = "dsi_lp_mode";
				zte,mdss-dsi-90fps-to-144fps-commands = [15 01 00 00 00 00 02 fe 00
					15 01 00 00 14 00 02 53 20
					15 01 00 00 00 00 02 fe 40
					15 01 00 00 00 00 02 bd 00
					15 01 00 00 00 00 02 fe 00
					15 01 00 00 32 00 02 03 06
					15 01 00 00 00 00 02 fe 40
					15 01 00 00 00 00 02 bd 07
					15 01 00 00 00 00 02 fe 00
					15 01 00 00 00 00 02 53 28
				];
				zte,mdss-dsi-90fps-to-144fps-commands-state = "dsi_lp_mode";
				zte,mdss-dsi-90fps-to-aod-commands = [15 01 00 00 00 00 02 fe 22
					15 01 00 00 00 00 02 5f 02
					15 01 00 00 00 00 02 fe 40
					15 01 00 00 00 00 02 bd 00
					15 01 00 00 00 00 02 fe 00
					05 01 00 00 00 00 02 39 00
					15 01 00 00 00 00 02 fe 00
				];
				zte,mdss-dsi-90fps-to-aod-commands-state = "dsi_lp_mode";
				zte,mdss-dsi-120fps-to-60fps-commands = [15 01 00 00 00 00 02 fe 00
					15 01 00 00 14 00 02 53 20
					15 01 00 00 32 00 02 03 00
					15 01 00 00 00 00 02 fe 00
					15 01 00 00 00 00 02 53 28
				];
				zte,mdss-dsi-120fps-to-60fps-commands-state = "dsi_lp_mode";
				zte,mdss-dsi-120fps-to-90fps-commands = [15 01 00 00 00 00 02 fe 00
					15 01 00 00 14 00 02 53 20
					15 01 00 00 32 00 02 03 00
					15 01 00 00 00 00 02 fe 40
					15 01 00 00 00 00 02 bd 05
					15 01 00 00 00 00 02 fe 00
					15 01 00 00 00 00 02 53 28
				];
				zte,mdss-dsi-120fps-to-90fps-commands-state = "dsi_lp_mode";
				zte,mdss-dsi-120fps-to-144fps-commands = [15 01 00 00 00 00 02 fe 40
					15 01 00 00 00 00 02 bd 07
					15 01 00 00 00 00 02 fe 00
				];
				zte,mdss-dsi-120fps-to-144fps-commands-state = "dsi_lp_mode";
				zte,mdss-dsi-120fps-to-aod-commands = [15 01 00 00 00 00 02 fe 22
					15 01 00 00 00 00 02 5f 02
					15 01 00 00 00 00 02 fe 00
					15 01 00 00 32 00 02 03 00
					15 01 00 00 00 00 02 fe 00
					05 01 00 00 00 00 02 39 00
				];
				zte,mdss-dsi-120fps-to-aod-commands-state = "dsi_lp_mode";
				zte,mdss-dsi-144fps-to-60fps-commands = [15 01 00 00 00 00 02 fe 00
					15 01 00 00 14 00 02 53 20
					15 01 00 00 00 00 02 fe 40
					15 01 00 00 00 00 02 bd 06
					15 01 00 00 00 00 02 fe 00
					15 01 00 00 32 00 02 03 00
					15 01 00 00 00 00 02 53 28
				];
				zte,mdss-dsi-144fps-to-60fps-commands-state = "dsi_lp_mode";
				zte,mdss-dsi-144fps-to-90fps-commands = [15 01 00 00 00 00 02 fe 00
					15 01 00 00 14 00 02 53 20
					15 01 00 00 00 00 02 fe 40
					15 01 00 00 00 00 02 bd 06
					15 01 00 00 00 00 02 fe 00
					15 01 00 00 32 00 02 03 00
					15 01 00 00 00 00 02 fe 40
					15 01 00 00 00 00 02 bd 05
					15 01 00 00 00 00 02 fe 00
					15 01 00 00 00 00 02 53 28
				];
				zte,mdss-dsi-144fps-to-90fps-commands-state = "dsi_lp_mode";
				zte,mdss-dsi-144fps-to-120fps-commands = [15 01 00 00 00 00 02 fe 40
					15 01 00 00 00 00 02 bd 06
					15 01 00 00 00 00 02 fe 00
				];
				zte,mdss-dsi-144fps-to-120fps-commands-state = "dsi_lp_mode";
				zte,mdss-dsi-144fps-to-aod-commands = [15 01 00 00 00 00 02 fe 22
					15 01 00 00 00 00 02 5f 02
					15 01 00 00 00 00 02 fe 40
					15 01 00 00 00 00 02 bd 06 
					15 01 00 00 00 00 02 fe 00
					15 01 00 00 32 00 02 03 00
					15 01 00 00 00 00 02 fe 00
					05 01 00 00 00 00 02 39 00
				];
				zte,mdss-dsi-144fps-to-aod-commands-state = "dsi_lp_mode";
				qcom,mdss-dsi-on-command = [15 01 00 00 00 00 02 fe 34
					15 01 00 00 00 00 02 47 03
					15 01 00 00 00 00 02 48 00
					15 01 00 00 00 00 02 00 00
					15 01 00 00 00 00 02 fe 34
					15 01 00 00 00 00 02 9f 38
					15 01 00 00 00 00 02 a0 04
					15 01 00 00 00 00 02 1e 33
					15 01 00 00 00 00 02 1f fc
					15 01 00 00 00 00 02 20 fc
					15 01 00 00 00 00 02 22 fc
					15 01 00 00 00 00 02 21 73
					15 01 00 00 00 00 02 23 f8
					15 01 00 00 00 00 02 24 77
					15 01 00 00 00 00 02 25 f8
					15 01 00 00 00 00 02 26 f8
					15 01 00 00 00 00 02 2f 00
					15 01 00 00 00 00 02 30 00
					15 01 00 00 00 00 02 31 00
					15 01 00 00 00 00 02 32 00
					15 01 00 00 00 00 02 33 00
					15 01 00 00 00 00 02 34 00
					15 01 00 00 00 00 02 35 01
					15 01 00 00 00 00 02 36 47
					15 01 00 00 00 00 02 37 02
					15 01 00 00 00 00 02 38 3e
					15 01 00 00 00 00 02 39 03
					15 01 00 00 00 00 02 3a 33
					15 01 00 00 00 00 02 3b 00
					15 01 00 00 00 00 02 3d 00
					15 01 00 00 00 00 02 3f 00
					15 01 00 00 00 00 02 40 00
					15 01 00 00 00 00 02 41 00
					15 01 00 00 00 00 02 42 00
					15 01 00 00 00 00 02 fe 34
					15 01 00 00 00 00 02 49 75
					15 01 00 00 00 00 02 fe 76
					15 01 00 00 00 00 02 00 3c
					15 01 00 00 00 00 02 09 03
					15 01 00 00 00 00 02 0a 00
					15 01 00 00 00 00 02 0b 06
					15 01 00 00 00 00 02 0c 70
					15 01 00 00 00 00 02 0d 76
					15 01 00 00 00 00 02 0e 0d
					15 01 00 00 00 00 02 0f 03
					15 01 00 00 00 00 02 10 00
					15 01 00 00 00 00 02 11 00
					15 01 00 00 00 00 02 12 80
					15 01 00 00 00 00 02 13 76
					15 01 00 00 00 00 02 14 0d
					15 01 00 00 00 00 02 fe 76
					15 01 00 00 00 00 02 70 fe
					15 01 00 00 00 00 02 71 40
					15 01 00 00 00 00 02 72 bd
					15 01 00 00 00 00 02 73 06
					15 01 00 00 00 00 02 74 ff
					15 01 00 00 00 00 02 75 01
					15 01 00 00 00 00 02 76 02
					15 01 00 00 00 00 02 77 fe
					15 01 00 00 00 00 02 78 62
					15 01 00 00 00 00 02 79 ee
					15 01 00 00 00 00 02 7a 20
					15 01 00 00 00 00 02 7b fe
					15 01 00 00 00 00 02 7c 00
					15 01 00 00 00 00 02 80 fe
					15 01 00 00 00 00 02 81 40
					15 01 00 00 00 00 02 82 bd
					15 01 00 00 00 00 02 83 00
					15 01 00 00 00 00 02 84 ff
					15 01 00 00 00 00 02 85 01
					15 01 00 00 00 00 02 86 02
					15 01 00 00 00 00 02 87 fe
					15 01 00 00 00 00 02 88 62
					15 01 00 00 00 00 02 89 ee
					15 01 00 00 00 00 02 8a 10
					15 01 00 00 00 00 02 8b fe
					15 01 00 00 00 00 02 8c 00
					15 01 00 00 00 00 02 fe d0
					15 01 00 00 00 00 02 14 c0
					15 01 00 00 00 00 02 15 c0
					15 01 00 00 00 00 02 fe 12
					15 01 00 00 00 00 02 83 20
					15 01 00 00 00 00 02 fe 00
					15 01 00 00 00 00 02 fa 01
					15 01 00 00 00 00 02 c2 08
					15 01 00 00 00 00 02 35 00
					39 01 00 00 00 00 03 51 00 00
					15 01 00 00 00 00 02 fe b0
					15 01 00 00 00 00 02 27 7f
					15 01 00 00 00 00 02 fe 62
					15 01 00 00 00 00 02 0f f0
					15 01 00 00 00 00 02 10 00
					15 01 00 00 00 00 02 fe 60
					15 01 00 00 00 00 02 7e 50
					15 01 00 00 00 00 02 80 98
					15 01 00 00 00 00 02 81 20
					15 01 00 00 00 00 02 0d 50
					15 01 00 00 00 00 02 0f 98
					15 01 00 00 00 00 02 10 20
					15 01 00 00 00 00 02 28 50
					15 01 00 00 00 00 02 2a 90
					15 01 00 00 00 00 02 2b 05
					15 01 00 00 00 00 02 47 50
					15 01 00 00 00 00 02 49 90
					15 01 00 00 00 00 02 4a 05
					15 01 00 00 00 00 02 fe 60
					15 01 00 00 00 00 02 92 e5
					15 01 00 00 00 00 02 94 00
					15 01 00 00 00 00 02 fe d4
					15 01 00 00 00 00 02 14 83
					15 01 00 00 00 00 02 1e 00
					15 01 00 00 00 00 02 1f 08
					15 01 00 00 00 00 02 20 0c
					15 01 00 00 00 00 02 21 03
					15 01 00 00 00 00 02 22 8e
					15 01 00 00 00 00 02 23 03
					15 01 00 00 00 00 02 24 e8
					15 01 00 00 00 00 02 25 00
					15 01 00 00 00 00 02 26 08
					15 01 00 00 00 00 02 27 0c
					15 01 00 00 00 00 02 28 03
					15 01 00 00 00 00 02 29 8e
					15 01 00 00 00 00 02 2a 03
					15 01 00 00 00 00 02 2b e8
					15 01 00 00 00 00 02 2d 00
					15 01 00 00 00 00 02 2f 08
					15 01 00 00 00 00 02 30 0c
					15 01 00 00 00 00 02 31 03
					15 01 00 00 00 00 02 32 8e
					15 01 00 00 00 00 02 33 03
					15 01 00 00 00 00 02 34 e8
					15 01 00 00 00 00 02 35 00
					15 01 00 00 00 00 02 36 08
					15 01 00 00 00 00 02 37 0c
					15 01 00 00 00 00 02 38 03
					15 01 00 00 00 00 02 39 8e
					15 01 00 00 00 00 02 3a 03
					15 01 00 00 00 00 02 3b e8
					15 01 00 00 00 00 02 fe 14
					15 01 00 00 00 00 02 a2 01
					15 01 00 00 00 00 02 51 80
					15 01 00 00 00 00 02 7b 00
					15 01 00 00 00 00 02 fe 40
					15 01 00 00 00 00 02 25 1a
					15 01 00 00 00 00 02 26 1d
					15 01 00 00 00 00 02 ac 84
					15 01 00 00 00 00 02 31 00
					15 01 00 00 00 00 02 35 00
					15 01 00 00 00 00 02 fe 00
					05 01 00 00 50 00 02 11 00
					05 01 00 00 0a 00 02 29 00
					15 01 00 00 00 00 02 fe 00
					15 01 00 00 32 00 02 03 06
					15 01 00 00 00 00 02 fe 00
				];
				qcom,mdss-dsi-off-command = [39 01 00 00 50 00 03 51 00 00
					05 01 00 00 32 00 02 28 00
					05 01 00 00 50 00 02 10 00
				];
				qcom,mdss-dsi-on-command-state = "dsi_lp_mode";
				qcom,mdss-dsi-off-command-state = "dsi_lp_mode";
				qcom,mdss-dsi-lp1-command = [15 01 00 00 00 00 02 fe 22
					15 01 00 00 00 00 02 5f 02
					15 01 00 00 00 00 02 fe 00
					15 01 00 00 32 00 02 03 00
					15 01 00 00 00 00 02 fe 00
					05 01 00 00 00 00 02 39 00
				];
				qcom,mdss-dsi-lp1-command-state = "dsi_lp_mode";
				qcom,mdss-dsi-nolp-command = [15 01 00 00 00 00 02 fe 22
					15 01 00 00 00 00 02 5f 01
					15 01 00 00 00 00 02 fe 40
					15 01 00 00 00 00 02 15 4f
					15 01 00 00 00 00 02 fe 00
					05 01 00 00 00 00 02 38 00
					15 01 00 00 00 00 02 fe 00
					15 01 00 00 32 00 02 03 06
					15 01 00 00 00 00 02 fe 00
				];
				qcom,mdss-dsi-nolp-command-state = "dsi_lp_mode";
				zte,mdss-dsi-aod-low-commands = [15 01 00 00 00 00 02 fe 00
					39 01 00 00 00 00 03 51 01 20
				];
				zte,mdss-dsi-aod-mid-commands = [15 01 00 00 00 00 02 fe 00
					39 01 00 00 00 00 03 51 07 ff
				];
				zte,mdss-dsi-aod-high-commands = [15 01 00 00 00 00 02 fe 00
					39 01 00 00 00 00 03 51 0f ff
				];
				zte,mdss-dsi-color-original-commands = [15 01 00 00 00 00 02 fe 12
					15 01 00 00 00 00 02 83 00
					15 01 00 00 05 00 02 fe 00
				];
				zte,mdss-dsi-color-srgb-commands = [15 01 00 00 00 00 02 fe 12
					15 01 00 00 00 00 02 83 10
					15 01 00 00 05 00 02 fe 00
				];
				zte,mdss-dsi-color-p3-commands = [15 01 00 00 00 00 02 fe 12
					15 01 00 00 00 00 02 83 20
					15 01 00 00 05 00 02 fe 00
				];
				zte,mdss-dsi-hbm-on-commands = [15 01 00 00 00 00 02 fe 00
					15 01 00 00 00 00 02 53 20
					39 01 00 00 00 00 03 51 0f ff
				];
				zte,mdss-dsi-hbm-off-commands = [15 01 00 00 00 00 02 53 20];
				zte,mdss-dsi-acl-off-commands = [15 01 00 00 00 00 02 fe 00
					15 01 00 00 00 00 02 55 00
				];
				zte,mdss-dsi-acl-low-commands = [15 01 00 00 00 00 02 fe 00
					15 01 00 00 00 00 02 55 11
				];
				zte,mdss-dsi-acl-mid-commands = [15 01 00 00 00 00 02 fe 00
					15 01 00 00 00 00 02 55 12
				];
				zte,mdss-dsi-acl-high-commands = [15 01 00 00 00 00 02 fe 00
					15 01 00 00 00 00 02 55 13
				];
				zte,mdss-dsi-acl-off-commands-state = "dsi_lp_mode";
				zte,mdss-dsi-acl-low-commands-state = "dsi_lp_mode";
				zte,mdss-dsi-acl-mid-commands-state = "dsi_lp_mode";
				zte,mdss-dsi-acl-high-commands-state = "dsi_lp_mode";
				zte,mdss-dsi-hbm-on-commands-state = "dsi_lp_mode";
				zte,mdss-dsi-hbm-off-commands-state = "dsi_lp_mode";
				zte,mdss-dsi-color-original-commands-state = "dsi_hs_mode";
				zte,mdss-dsi-color-srgb-commands-state = "dsi_hs_mode";
				zte,mdss-dsi-color-p3-commands-state = "dsi_hs_mode";
				zte,mdss-dsi-aod-low-commands-state = "dsi_lp_mode";
				zte,mdss-dsi-aod-mid-commands-state = "dsi_lp_mode";
				zte,mdss-dsi-aod-high-commands-state = "dsi_lp_mode";
				qcom,compression-mode = "dsc";
				qcom,mdss-dsc-slice-height = <12>;
				qcom,mdss-dsc-slice-width = <540>;
				qcom,mdss-dsc-slice-per-pkt = <2>;
				qcom,mdss-dsc-bit-per-component = <10>;
				qcom,mdss-dsc-bit-per-pixel = <8>;
				qcom,mdss-dsc-block-prediction-enable;
				qcom,mdss-dsi-panel-phy-timings = [00 1a 07 06 16 15 07 07 07 02 04 00 17 0b];
				qcom,display-topology = <2 2 1>;
				qcom,default-topology-index = <0>;
			};

			timing@3 {
				qcom,mdss-dsi-panel-width = <1080>;
				qcom,mdss-dsi-panel-height = <2400>;
				qcom,mdss-dsi-h-front-porch = <26>;
				qcom,mdss-dsi-h-back-porch = <36>;
				qcom,mdss-dsi-h-pulse-width = <2>;
				qcom,mdss-dsi-h-sync-skew = <0>;
				qcom,mdss-dsi-v-back-porch = <12>;
				qcom,mdss-dsi-v-front-porch = <12>;
				qcom,mdss-dsi-v-pulse-width = <8>;
				qcom,mdss-dsi-h-sync-pulse = <0>;
				qcom,mdss-dsi-h-left-border = <0>;
				qcom,mdss-dsi-h-right-border = <0>;
				qcom,mdss-dsi-v-top-border = <0>;
				qcom,mdss-dsi-v-bottom-border = <0>;
				qcom,mdss-dsi-panel-framerate = <144>;
				qcom,mdss-dsi-panel-clockrate = <925800000>;
				zte,mdss-dsi-60fps-to-90fps-commands = [15 01 00 00 00 00 02 fe 40
					15 01 00 00 00 00 02 bd 05
					15 01 00 00 00 00 02 fe 00
				];
				zte,mdss-dsi-60fps-to-90fps-commands-state = "dsi_lp_mode";
				zte,mdss-dsi-60fps-to-120fps-commands = [15 01 00 00 00 00 02 fe 00
					15 01 00 00 14 00 02 53 20
					15 01 00 00 32 00 02 03 06
					15 01 00 00 00 00 02 fe 00
					15 01 00 00 00 00 02 53 28
				];
				zte,mdss-dsi-60fps-to-120fps-commands-state = "dsi_lp_mode";
				zte,mdss-dsi-60fps-to-144fps-commands = [15 01 00 00 00 00 02 fe 00
					15 01 00 00 14 00 02 53 20
					15 01 00 00 32 00 02 03 06
					15 01 00 00 00 00 02 fe 40
					15 01 00 00 00 00 02 bd 07
					15 01 00 00 00 00 02 fe 00
					15 01 00 00 00 00 02 53 28
				];
				zte,mdss-dsi-60fps-to-144fps-commands-state = "dsi_lp_mode";
				zte,mdss-dsi-60fps-to-aod-commands = [15 01 00 00 00 00 02 fe 22 
					15 01 00 00 00 00 02 5f 03
					15 01 00 00 00 00 02 fe 40
					15 01 00 00 00 00 02 15 13
					15 01 00 00 00 00 02 fe 00
					05 01 00 00 00 00 02 39 00
					15 01 00 00 00 00 02 fe 00
				];
				zte,mdss-dsi-60fps-to-aod-commands-state = "dsi_lp_mode";
				zte,mdss-dsi-90fps-to-60fps-commands = [15 01 00 00 00 00 02 fe 40
					15 01 00 00 00 00 02 bd 00
					15 01 00 00 00 00 02 fe 00
				];
				zte,mdss-dsi-90fps-to-60fps-commands-state = "dsi_lp_mode";
				zte,mdss-dsi-90fps-to-120fps-commands = [15 01 00 00 00 00 02 fe 00
					15 01 00 00 14 00 02 53 20
					15 01 00 00 00 00 02 fe 40
					15 01 00 00 00 00 02 bd 00
					15 01 00 00 00 00 02 fe 00
					15 01 00 00 32 00 02 03 06
					15 01 00 00 00 00 02 fe 00
					15 01 00 00 00 00 02 53 28
				];
				zte,mdss-dsi-90fps-to-120fps-commands-state = "dsi_lp_mode";
				zte,mdss-dsi-90fps-to-144fps-commands = [15 01 00 00 00 00 02 fe 00 
					15 01 00 00 14 00 02 53 20
					15 01 00 00 00 00 02 fe 40
					15 01 00 00 00 00 02 bd 00
					15 01 00 00 00 00 02 fe 00
					15 01 00 00 32 00 02 03 06
					15 01 00 00 00 00 02 fe 40
					15 01 00 00 00 00 02 bd 07
					15 01 00 00 00 00 02 fe 00
					15 01 00 00 00 00 02 53 28
				];
				zte,mdss-dsi-90fps-to-144fps-commands-state = "dsi_lp_mode";
				zte,mdss-dsi-90fps-to-aod-commands = [15 01 00 00 00 00 02 fe 22
					15 01 00 00 00 00 02 5f 02
					15 01 00 00 00 00 02 fe 40
					15 01 00 00 00 00 02 bd 00
					15 01 00 00 00 00 02 fe 00
					05 01 00 00 00 00 02 39 00
					15 01 00 00 00 00 02 fe 00
				];
				zte,mdss-dsi-90fps-to-aod-commands-state = "dsi_lp_mode";
				zte,mdss-dsi-120fps-to-60fps-commands = [15 01 00 00 00 00 02 fe 00
					15 01 00 00 14 00 02 53 20
					15 01 00 00 32 00 02 03 00
					15 01 00 00 00 00 02 fe 00
					15 01 00 00 00 00 02 53 28
				];
				zte,mdss-dsi-120fps-to-60fps-commands-state = "dsi_lp_mode";
				zte,mdss-dsi-120fps-to-90fps-commands = [15 01 00 00 00 00 02 fe 00
					15 01 00 00 14 00 02 53 20
					15 01 00 00 32 00 02 03 00
					15 01 00 00 00 00 02 fe 40
					15 01 00 00 00 00 02 bd 05
					15 01 00 00 00 00 02 fe 00
					15 01 00 00 00 00 02 53 28
				];
				zte,mdss-dsi-120fps-to-90fps-commands-state = "dsi_lp_mode";
				zte,mdss-dsi-120fps-to-144fps-commands = [15 01 00 00 00 00 02 fe 40
					15 01 00 00 00 00 02 bd 07
					15 01 00 00 00 00 02 fe 00
				];
				zte,mdss-dsi-120fps-to-144fps-commands-state = "dsi_lp_mode";
				zte,mdss-dsi-120fps-to-aod-commands = [15 01 00 00 00 00 02 fe 22
					15 01 00 00 00 00 02 5f 02
					15 01 00 00 00 00 02 fe 00
					15 01 00 00 32 00 02 03 00
					15 01 00 00 00 00 02 fe 00
					05 01 00 00 00 00 02 39 00
				];
				zte,mdss-dsi-120fps-to-aod-commands-state = "dsi_lp_mode";
				zte,mdss-dsi-144fps-to-60fps-commands = [15 01 00 00 00 00 02 fe 00
					15 01 00 00 14 00 02 53 20
					15 01 00 00 00 00 02 fe 40
					15 01 00 00 00 00 02 bd 06
					15 01 00 00 00 00 02 fe 00
					15 01 00 00 32 00 02 03 00
					15 01 00 00 00 00 02 53 28
				];
				zte,mdss-dsi-144fps-to-60fps-commands-state = "dsi_lp_mode";
				zte,mdss-dsi-144fps-to-90fps-commands = [15 01 00 00 00 00 02 fe 00
					15 01 00 00 14 00 02 53 20
					15 01 00 00 00 00 02 fe 40
					15 01 00 00 00 00 02 bd 06
					15 01 00 00 00 00 02 fe 00
					15 01 00 00 32 00 02 03 00
					15 01 00 00 00 00 02 fe 40
					15 01 00 00 00 00 02 bd 05
					15 01 00 00 00 00 02 fe 00
					15 01 00 00 00 00 02 53 28
				];
				zte,mdss-dsi-144fps-to-90fps-commands-state = "dsi_lp_mode";
				zte,mdss-dsi-144fps-to-120fps-commands = [15 01 00 00 00 00 02 fe 40
					15 01 00 00 00 00 02 bd 06
					15 01 00 00 00 00 02 fe 00
				];
				zte,mdss-dsi-144fps-to-120fps-commands-state = "dsi_lp_mode";
				zte,mdss-dsi-144fps-to-aod-commands = [15 01 00 00 00 00 02 fe 22
					15 01 00 00 00 00 02 5f 02
					15 01 00 00 00 00 02 fe 40
					15 01 00 00 00 00 02 bd 06
					15 01 00 00 00 00 02 fe 00
					15 01 00 00 32 00 02 03 00
					15 01 00 00 00 00 02 fe 00
					05 01 00 00 00 00 02 39 00
				];
				zte,mdss-dsi-144fps-to-aod-commands-state = "dsi_lp_mode";
				qcom,mdss-dsi-on-command = [15 01 00 00 00 00 02 fe 34
					15 01 00 00 00 00 02 47 03
					15 01 00 00 00 00 02 48 00
					15 01 00 00 00 00 02 00 00
					15 01 00 00 00 00 02 fe 34
					15 01 00 00 00 00 02 9f 38
					15 01 00 00 00 00 02 a0 04
					15 01 00 00 00 00 02 1e 33
					15 01 00 00 00 00 02 1f fc
					15 01 00 00 00 00 02 20 fc
					15 01 00 00 00 00 02 22 fc
					15 01 00 00 00 00 02 21 73
					15 01 00 00 00 00 02 23 f8
					15 01 00 00 00 00 02 24 77
					15 01 00 00 00 00 02 25 f8
					15 01 00 00 00 00 02 26 f8
					15 01 00 00 00 00 02 2f 00
					15 01 00 00 00 00 02 30 00
					15 01 00 00 00 00 02 31 00
					15 01 00 00 00 00 02 32 00
					15 01 00 00 00 00 02 33 00
					15 01 00 00 00 00 02 34 00
					15 01 00 00 00 00 02 35 01
					15 01 00 00 00 00 02 36 47
					15 01 00 00 00 00 02 37 02
					15 01 00 00 00 00 02 38 3e
					15 01 00 00 00 00 02 39 03
					15 01 00 00 00 00 02 3a 33
					15 01 00 00 00 00 02 3b 00
					15 01 00 00 00 00 02 3d 00
					15 01 00 00 00 00 02 3f 00
					15 01 00 00 00 00 02 40 00
					15 01 00 00 00 00 02 41 00
					15 01 00 00 00 00 02 42 00
					15 01 00 00 00 00 02 fe 34
					15 01 00 00 00 00 02 49 75
					15 01 00 00 00 00 02 fe 76
					15 01 00 00 00 00 02 00 3c
					15 01 00 00 00 00 02 09 03
					15 01 00 00 00 00 02 0a 00
					15 01 00 00 00 00 02 0b 06
					15 01 00 00 00 00 02 0c 70
					15 01 00 00 00 00 02 0d 76
					15 01 00 00 00 00 02 0e 0d
					15 01 00 00 00 00 02 0f 03
					15 01 00 00 00 00 02 10 00
					15 01 00 00 00 00 02 11 00
					15 01 00 00 00 00 02 12 80
					15 01 00 00 00 00 02 13 76
					15 01 00 00 00 00 02 14 0d
					15 01 00 00 00 00 02 fe 76
					15 01 00 00 00 00 02 70 fe
					15 01 00 00 00 00 02 71 40
					15 01 00 00 00 00 02 72 bd
					15 01 00 00 00 00 02 73 06
					15 01 00 00 00 00 02 74 ff
					15 01 00 00 00 00 02 75 01
					15 01 00 00 00 00 02 76 02
					15 01 00 00 00 00 02 77 fe
					15 01 00 00 00 00 02 78 62
					15 01 00 00 00 00 02 79 ee
					15 01 00 00 00 00 02 7a 20
					15 01 00 00 00 00 02 7b fe
					15 01 00 00 00 00 02 7c 00
					15 01 00 00 00 00 02 80 fe
					15 01 00 00 00 00 02 81 40
					15 01 00 00 00 00 02 82 bd
					15 01 00 00 00 00 02 83 00
					15 01 00 00 00 00 02 84 ff
					15 01 00 00 00 00 02 85 01
					15 01 00 00 00 00 02 86 02
					15 01 00 00 00 00 02 87 fe
					15 01 00 00 00 00 02 88 62
					15 01 00 00 00 00 02 89 ee
					15 01 00 00 00 00 02 8a 10
					15 01 00 00 00 00 02 8b fe
					15 01 00 00 00 00 02 8c 00
					15 01 00 00 00 00 02 fe d0
					15 01 00 00 00 00 02 14 c0
					15 01 00 00 00 00 02 15 c0
					15 01 00 00 00 00 02 fe 12
					15 01 00 00 00 00 02 83 20
					15 01 00 00 00 00 02 fe 00
					15 01 00 00 00 00 02 fa 01
					15 01 00 00 00 00 02 c2 08
					15 01 00 00 00 00 02 35 00
					39 01 00 00 00 00 03 51 00 00
					15 01 00 00 00 00 02 fe b0
					15 01 00 00 00 00 02 27 7f
					15 01 00 00 00 00 02 fe 62
					15 01 00 00 00 00 02 0f f0
					15 01 00 00 00 00 02 10 00
					15 01 00 00 00 00 02 fe 60
					15 01 00 00 00 00 02 7e 50
					15 01 00 00 00 00 02 80 98
					15 01 00 00 00 00 02 81 20
					15 01 00 00 00 00 02 0d 50
					15 01 00 00 00 00 02 0f 98
					15 01 00 00 00 00 02 10 20
					15 01 00 00 00 00 02 28 50
					15 01 00 00 00 00 02 2a 90
					15 01 00 00 00 00 02 2b 05
					15 01 00 00 00 00 02 47 50
					15 01 00 00 00 00 02 49 90
					15 01 00 00 00 00 02 4a 05
					15 01 00 00 00 00 02 fe 60
					15 01 00 00 00 00 02 92 e5
					15 01 00 00 00 00 02 94 00
					15 01 00 00 00 00 02 fe d4
					15 01 00 00 00 00 02 14 83
					15 01 00 00 00 00 02 1e 00
					15 01 00 00 00 00 02 1f 08
					15 01 00 00 00 00 02 20 0c
					15 01 00 00 00 00 02 21 03
					15 01 00 00 00 00 02 22 8e
					15 01 00 00 00 00 02 23 03
					15 01 00 00 00 00 02 24 e8
					15 01 00 00 00 00 02 25 00
					15 01 00 00 00 00 02 26 08
					15 01 00 00 00 00 02 27 0c
					15 01 00 00 00 00 02 28 03
					15 01 00 00 00 00 02 29 8e
					15 01 00 00 00 00 02 2a 03
					15 01 00 00 00 00 02 2b e8
					15 01 00 00 00 00 02 2d 00
					15 01 00 00 00 00 02 2f 08
					15 01 00 00 00 00 02 30 0c
					15 01 00 00 00 00 02 31 03
					15 01 00 00 00 00 02 32 8e
					15 01 00 00 00 00 02 33 03
					15 01 00 00 00 00 02 34 e8
					15 01 00 00 00 00 02 35 00
					15 01 00 00 00 00 02 36 08
					15 01 00 00 00 00 02 37 0c
					15 01 00 00 00 00 02 38 03
					15 01 00 00 00 00 02 39 8e
					15 01 00 00 00 00 02 3a 03
					15 01 00 00 00 00 02 3b e8
					15 01 00 00 00 00 02 fe 14
					15 01 00 00 00 00 02 a2 01
					15 01 00 00 00 00 02 51 80
					15 01 00 00 00 00 02 7b 00
					15 01 00 00 00 00 02 fe 40
					15 01 00 00 00 00 02 25 1a
					15 01 00 00 00 00 02 26 1d
					15 01 00 00 00 00 02 ac 84
					15 01 00 00 00 00 02 31 00
					15 01 00 00 00 00 02 35 00
					15 01 00 00 00 00 02 fe 00
					05 01 00 00 50 00 02 11 00
					05 01 00 00 0a 00 02 29 00
					15 01 00 00 00 00 02 fe 00
					15 01 00 00 32 00 02 03 06
					15 01 00 00 00 00 02 bd 05
					15 01 00 00 00 00 02 fe 40
					15 01 00 00 00 00 02 bd 07
					15 01 00 00 00 00 02 fe 00
				];
				qcom,mdss-dsi-off-command = [39 01 00 00 50 00 03 51 00 00
					05 01 00 00 32 00 02 28 00
					05 01 00 00 50 00 02 10 00
				];
				qcom,mdss-dsi-on-command-state = "dsi_lp_mode";
				qcom,mdss-dsi-off-command-state = "dsi_lp_mode";
				qcom,mdss-dsi-lp1-command = [15 01 00 00 00 00 02 fe 22
					15 01 00 00 00 00 02 5f 02
					15 01 00 00 00 00 02 fe 40
					15 01 00 00 00 00 02 bd 06
					15 01 00 00 00 00 02 fe 00
					15 01 00 00 32 00 02 03 00
					15 01 00 00 00 00 02 fe 00
					05 01 00 00 00 00 02 39 00
				];
				qcom,mdss-dsi-lp1-command-state = "dsi_lp_mode";
				qcom,mdss-dsi-nolp-command = [15 01 00 00 00 00 02 fe 22
					15 01 00 00 00 00 02 5f 01
					15 01 00 00 00 00 02 fe 40
					15 01 00 00 00 00 02 15 4f
					15 01 00 00 00 00 02 fe 00
					05 01 00 00 00 00 02 38 00
					15 01 00 00 32 00 02 03 06
					15 01 00 00 00 00 02 bd 05
					15 01 00 00 00 00 02 fe 40
					15 01 00 00 00 00 02 bd 07
					15 01 00 00 00 00 02 fe 00
				];
				qcom,mdss-dsi-nolp-command-state = "dsi_lp_mode";
				zte,mdss-dsi-aod-low-commands = [15 01 00 00 00 00 02 fe 00
					39 01 00 00 00 00 03 51 01 20
				];
				zte,mdss-dsi-aod-mid-commands = [15 01 00 00 00 00 02 fe 00
					39 01 00 00 00 00 03 51 07 ff
				];
				zte,mdss-dsi-aod-high-commands = [15 01 00 00 00 00 02 fe 00
					39 01 00 00 00 00 03 51 0f ff
				];
				zte,mdss-dsi-color-original-commands = [15 01 00 00 00 00 02 fe 12
					15 01 00 00 00 00 02 83 00
					15 01 00 00 05 00 02 fe 00
				];
				zte,mdss-dsi-color-srgb-commands = [15 01 00 00 00 00 02 fe 12
					15 01 00 00 00 00 02 83 10
					15 01 00 00 05 00 02 fe 00
				];
				zte,mdss-dsi-color-p3-commands = [15 01 00 00 00 00 02 fe 12
					15 01 00 00 00 00 02 83 20
					15 01 00 00 05 00 02 fe 00
				];
				zte,mdss-dsi-hbm-on-commands = [15 01 00 00 00 00 02 fe 00
					15 01 00 00 00 00 02 53 20
					39 01 00 00 00 00 03 51 0f ff
				];
				zte,mdss-dsi-hbm-off-commands = [15 01 00 00 00 00 02 53 20];
				zte,mdss-dsi-acl-off-commands = [15 01 00 00 00 00 02 fe 00
					15 01 00 00 00 00 02 55 00
				];
				zte,mdss-dsi-acl-low-commands = [15 01 00 00 00 00 02 fe 00
					15 01 00 00 00 00 02 55 11
				];
				zte,mdss-dsi-acl-mid-commands = [15 01 00 00 00 00 02 fe 00
					15 01 00 00 00 00 02 55 12
				];
				zte,mdss-dsi-acl-high-commands = [15 01 00 00 00 00 02 fe 00
					15 01 00 00 00 00 02 55 13
				];
				zte,mdss-dsi-acl-off-commands-state = "dsi_lp_mode";
				zte,mdss-dsi-acl-low-commands-state = "dsi_lp_mode";
				zte,mdss-dsi-acl-mid-commands-state = "dsi_lp_mode";
				zte,mdss-dsi-acl-high-commands-state = "dsi_lp_mode";
				zte,mdss-dsi-hbm-on-commands-state = "dsi_lp_mode";
				zte,mdss-dsi-hbm-off-commands-state = "dsi_lp_mode";
				zte,mdss-dsi-color-original-commands-state = "dsi_hs_mode";
				zte,mdss-dsi-color-srgb-commands-state = "dsi_hs_mode";
				zte,mdss-dsi-color-p3-commands-state = "dsi_hs_mode";
				zte,mdss-dsi-aod-low-commands-state = "dsi_lp_mode";
				zte,mdss-dsi-aod-mid-commands-state = "dsi_lp_mode";
				zte,mdss-dsi-aod-high-commands-state = "dsi_lp_mode";
				qcom,compression-mode = "dsc";
				qcom,mdss-dsc-slice-height = <12>;
				qcom,mdss-dsc-slice-width = <540>;
				qcom,mdss-dsc-slice-per-pkt = <2>;
				qcom,mdss-dsc-bit-per-component = <10>;
				qcom,mdss-dsc-bit-per-pixel = <8>;
				qcom,mdss-dsc-block-prediction-enable;
				qcom,mdss-dsi-panel-phy-timings = [00 1f 08 07 18 16 08 08 08 02 04 00 1a 0c];
				qcom,display-topology = <2 2 1>;
				qcom,default-topology-index = <0>;
			};
		};
	};
};
